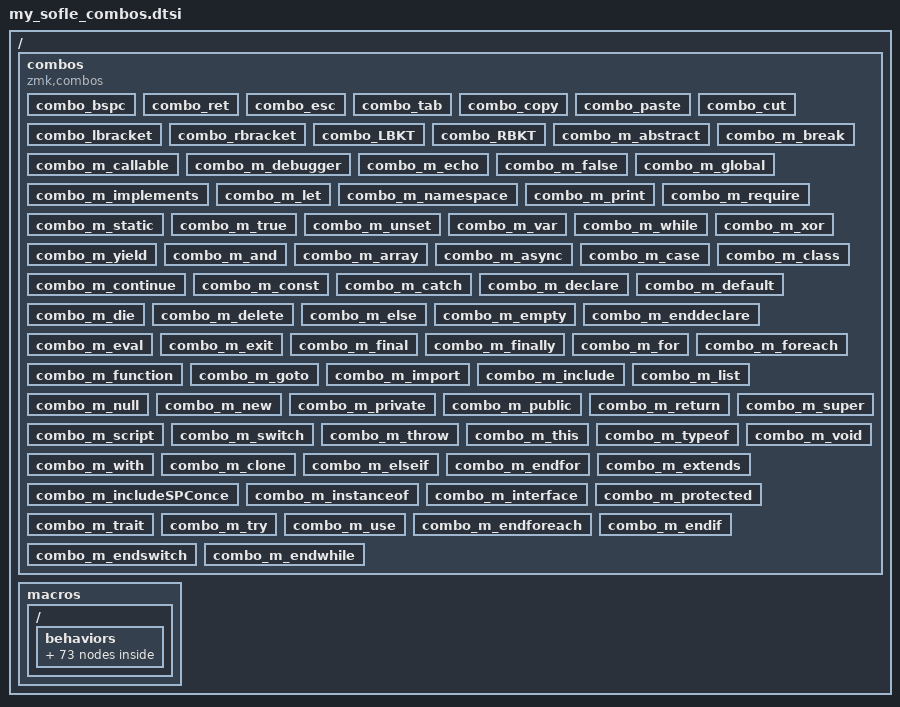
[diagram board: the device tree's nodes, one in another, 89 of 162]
/*                       58 KEY MATRIX 

  ╭────────────────────────────┬────────────────────────────╮
  │  0   1   2   3   4   5     │      6   7   8   9  10  11 │
  │ 12  13  14  15  16  17     │     18  19  20  21  22  23 │
  │ 24  25  26  27  28  29     │     30  31  32  33  34  35 │
  │ 36  37  38  39  40  41  42 │ 43  44  45  46  47  48  49 │
  ╰───────────╮ 50  51  52  53 │ 54  55  56  57 ╭───────────╯
              ╰────────────────┴────────────────╯            */


#define P_Q 13
#define P_W 14
#define P_F 15
#define P_P 16
#define P_B 17
#define P_J 18
#define P_L 19
#define P_U 20
#define P_Y 21
#define P_SEMI 22
#define P_A 25
#define P_R 26
#define P_S 27
#define P_T 28
#define P_G 29
#define P_M 30
#define P_N 31
#define P_E 32
#define P_I 33
#define P_O 34
#define P_Z 37
#define P_X 38
#define P_C 39
#define P_D 40
#define P_V 41
#define P_K 44
#define P_H 45
#define P_COMA 46
#define P_DOT 47
#define P_SQT 48
#define P_COMBO 52 55
#define COMBO_TIMEOUT 200
#define MACRO_TAP 10
#define MACRO_WAIT 0

/ {
    combos {
        compatible = "zmk,combos";
        combo_bspc {
            timeout-ms = <50>;
            key-positions = <19 20>;
            bindings = <&kp BSPC>;
            layers = <0>;
        };
        combo_ret {
            timeout-ms = <50>;
            key-positions = <20 21>;
            bindings = <&kp RET>;
            layers = <0>;
        };
        combo_esc {
            timeout-ms = <50>;
            key-positions = <14 15>;
            bindings = <&kp ESC>;
            layers = <0>;
        };
        combo_tab {
            timeout-ms = <50>;
            key-positions = <15 16>;
            bindings = <&kp TAB>;
            layers = <0>;
        };
        combo_copy {
            timeout-ms = <50>;
            key-positions = <38 39>;
            bindings = <&kp LC(INS)>;
            layers = <4>;
        };
        combo_paste {
            timeout-ms = <50>;
            key-positions = <39 40>;
            bindings = <&kp LS(INS)>;
            layers = <4>;
        };
        combo_cut {
            timeout-ms = <50>;
            key-positions = <37 38>;
            bindings = <&kp LS(DEL)>;
            layers = <4>;
        };
        combo_lbracket {
            timeout-ms = <50>;
            key-positions = <40 41>;
            bindings = <&kp LPAR>;
            layers = <0>;
        };
        combo_rbracket {
            timeout-ms = <50>;
            key-positions = <44 45>;
            bindings = <&kp RPAR>;
            layers = <0>;
        };
        combo_LBKT {
            timeout-ms = <50>;
            key-positions = <16 17>;
            bindings = <&kp LBKT>;
            layers = <0>;
        };
        combo_RBKT {
            timeout-ms = <50>;
            key-positions = <18 19>;
            bindings = <&kp RBKT>;
            layers = <0>;
        };
        // COMBOS START
    combo_m_abstract {
      timeout-ms = <COMBO_TIMEOUT>;
      key-positions = <P_COMBO P_A>;
      bindings = <&m_abstract>;
      layers = <0>;
    };
    combo_m_break {
      timeout-ms = <COMBO_TIMEOUT>;
      key-positions = <P_COMBO P_B>;
      bindings = <&m_break>;
      layers = <0>;
    };
    combo_m_callable {
      timeout-ms = <COMBO_TIMEOUT>;
      key-positions = <P_COMBO P_C>;
      bindings = <&m_callable>;
      layers = <0>;
    };
    combo_m_debugger {
      timeout-ms = <COMBO_TIMEOUT>;
      key-positions = <P_COMBO P_D>;
      bindings = <&m_debugger>;
      layers = <0>;
    };
    combo_m_echo {
      timeout-ms = <COMBO_TIMEOUT>;
      key-positions = <P_COMBO P_E>;
      bindings = <&m_echo>;
      layers = <0>;
    };
    combo_m_false {
      timeout-ms = <COMBO_TIMEOUT>;
      key-positions = <P_COMBO P_F>;
      bindings = <&m_false>;
      layers = <0>;
    };
    combo_m_global {
      timeout-ms = <COMBO_TIMEOUT>;
      key-positions = <P_COMBO P_G>;
      bindings = <&m_global>;
      layers = <0>;
    };
    combo_m_implements {
      timeout-ms = <COMBO_TIMEOUT>;
      key-positions = <P_COMBO P_I>;
      bindings = <&m_implements>;
      layers = <0>;
    };
    combo_m_let {
      timeout-ms = <COMBO_TIMEOUT>;
      key-positions = <P_COMBO P_L>;
      bindings = <&m_let>;
      layers = <0>;
    };
    combo_m_namespace {
      timeout-ms = <COMBO_TIMEOUT>;
      key-positions = <P_COMBO P_N>;
      bindings = <&m_namespace>;
      layers = <0>;
    };
    combo_m_print {
      timeout-ms = <COMBO_TIMEOUT>;
      key-positions = <P_COMBO P_P>;
      bindings = <&m_print>;
      layers = <0>;
    };
    combo_m_require {
      timeout-ms = <COMBO_TIMEOUT>;
      key-positions = <P_COMBO P_R>;
      bindings = <&m_require>;
      layers = <0>;
    };
    combo_m_static {
      timeout-ms = <COMBO_TIMEOUT>;
      key-positions = <P_COMBO P_S>;
      bindings = <&m_static>;
      layers = <0>;
    };
    combo_m_true {
      timeout-ms = <COMBO_TIMEOUT>;
      key-positions = <P_COMBO P_T>;
      bindings = <&m_true>;
      layers = <0>;
    };
    combo_m_unset {
      timeout-ms = <COMBO_TIMEOUT>;
      key-positions = <P_COMBO P_U>;
      bindings = <&m_unset>;
      layers = <0>;
    };
    combo_m_var {
      timeout-ms = <COMBO_TIMEOUT>;
      key-positions = <P_COMBO P_V>;
      bindings = <&m_var>;
      layers = <0>;
    };
    combo_m_while {
      timeout-ms = <COMBO_TIMEOUT>;
      key-positions = <P_COMBO P_W>;
      bindings = <&m_while>;
      layers = <0>;
    };
    combo_m_xor {
      timeout-ms = <COMBO_TIMEOUT>;
      key-positions = <P_COMBO P_X>;
      bindings = <&m_xor>;
      layers = <0>;
    };
    combo_m_yield {
      timeout-ms = <COMBO_TIMEOUT>;
      key-positions = <P_COMBO P_Y>;
      bindings = <&m_yield>;
      layers = <0>;
    };
    combo_m_and {
      timeout-ms = <COMBO_TIMEOUT>;
      key-positions = <P_COMBO P_A P_N>;
      bindings = <&m_and>;
      layers = <0>;
    };
    combo_m_array {
      timeout-ms = <COMBO_TIMEOUT>;
      key-positions = <P_COMBO P_A P_R>;
      bindings = <&m_array>;
      layers = <0>;
    };
    combo_m_async {
      timeout-ms = <COMBO_TIMEOUT>;
      key-positions = <P_COMBO P_A P_Y>;
      bindings = <&m_async>;
      layers = <0>;
    };
    combo_m_case {
      timeout-ms = <COMBO_TIMEOUT>;
      key-positions = <P_COMBO P_C P_A>;
      bindings = <&m_case>;
      layers = <0>;
    };
    combo_m_class {
      timeout-ms = <COMBO_TIMEOUT>;
      key-positions = <P_COMBO P_C P_L>;
      bindings = <&m_class>;
      layers = <0>;
    };
    combo_m_continue {
      timeout-ms = <COMBO_TIMEOUT>;
      key-positions = <P_COMBO P_C P_N>;
      bindings = <&m_continue>;
      layers = <0>;
    };
    combo_m_const {
      timeout-ms = <COMBO_TIMEOUT>;
      key-positions = <P_COMBO P_C P_O>;
      bindings = <&m_const>;
      layers = <0>;
    };
    combo_m_catch {
      timeout-ms = <COMBO_TIMEOUT>;
      key-positions = <P_COMBO P_C P_T>;
      bindings = <&m_catch>;
      layers = <0>;
    };
    combo_m_declare {
      timeout-ms = <COMBO_TIMEOUT>;
      key-positions = <P_COMBO P_D P_E>;
      bindings = <&m_declare>;
      layers = <0>;
    };
    combo_m_default {
      timeout-ms = <COMBO_TIMEOUT>;
      key-positions = <P_COMBO P_D P_F>;
      bindings = <&m_default>;
      layers = <0>;
    };
    combo_m_die {
      timeout-ms = <COMBO_TIMEOUT>;
      key-positions = <P_COMBO P_D P_I>;
      bindings = <&m_die>;
      layers = <0>;
    };
    combo_m_delete {
      timeout-ms = <COMBO_TIMEOUT>;
      key-positions = <P_COMBO P_D P_L>;
      bindings = <&m_delete>;
      layers = <0>;
    };
    combo_m_else {
      timeout-ms = <COMBO_TIMEOUT>;
      key-positions = <P_COMBO P_E P_L>;
      bindings = <&m_else>;
      layers = <0>;
    };
    combo_m_empty {
      timeout-ms = <COMBO_TIMEOUT>;
      key-positions = <P_COMBO P_E P_M>;
      bindings = <&m_empty>;
      layers = <0>;
    };
    combo_m_enddeclare {
      timeout-ms = <COMBO_TIMEOUT>;
      key-positions = <P_COMBO P_E P_N>;
      bindings = <&m_enddeclare>;
      layers = <0>;
    };
    combo_m_eval {
      timeout-ms = <COMBO_TIMEOUT>;
      key-positions = <P_COMBO P_E P_V>;
      bindings = <&m_eval>;
      layers = <0>;
    };
    combo_m_exit {
      timeout-ms = <COMBO_TIMEOUT>;
      key-positions = <P_COMBO P_E P_X>;
      bindings = <&m_exit>;
      layers = <0>;
    };
    combo_m_final {
      timeout-ms = <COMBO_TIMEOUT>;
      key-positions = <P_COMBO P_F P_I>;
      bindings = <&m_final>;
      layers = <0>;
    };
    combo_m_finally {
      timeout-ms = <COMBO_TIMEOUT>;
      key-positions = <P_COMBO P_F P_N>;
      bindings = <&m_finally>;
      layers = <0>;
    };
    combo_m_for {
      timeout-ms = <COMBO_TIMEOUT>;
      key-positions = <P_COMBO P_F P_O>;
      bindings = <&m_for>;
      layers = <0>;
    };
    combo_m_foreach {
      timeout-ms = <COMBO_TIMEOUT>;
      key-positions = <P_COMBO P_F P_R>;
      bindings = <&m_foreach>;
      layers = <0>;
    };
    combo_m_function {
      timeout-ms = <COMBO_TIMEOUT>;
      key-positions = <P_COMBO P_F P_U>;
      bindings = <&m_function>;
      layers = <0>;
    };
    combo_m_goto {
      timeout-ms = <COMBO_TIMEOUT>;
      key-positions = <P_COMBO P_G P_O>;
      bindings = <&m_goto>;
      layers = <0>;
    };
    combo_m_import {
      timeout-ms = <COMBO_TIMEOUT>;
      key-positions = <P_COMBO P_I P_M>;
      bindings = <&m_import>;
      layers = <0>;
    };
    combo_m_include {
      timeout-ms = <COMBO_TIMEOUT>;
      key-positions = <P_COMBO P_I P_N>;
      bindings = <&m_include>;
      layers = <0>;
    };
    combo_m_list {
      timeout-ms = <COMBO_TIMEOUT>;
      key-positions = <P_COMBO P_L P_I>;
      bindings = <&m_list>;
      layers = <0>;
    };
    combo_m_null {
      timeout-ms = <COMBO_TIMEOUT>;
      key-positions = <P_COMBO P_N P_U>;
      bindings = <&m_null>;
      layers = <0>;
    };
    combo_m_new {
      timeout-ms = <COMBO_TIMEOUT>;
      key-positions = <P_COMBO P_N P_W>;
      bindings = <&m_new>;
      layers = <0>;
    };
    combo_m_private {
      timeout-ms = <COMBO_TIMEOUT>;
      key-positions = <P_COMBO P_P P_R>;
      bindings = <&m_private>;
      layers = <0>;
    };
    combo_m_public {
      timeout-ms = <COMBO_TIMEOUT>;
      key-positions = <P_COMBO P_P P_U>;
      bindings = <&m_public>;
      layers = <0>;
    };
    combo_m_return {
      timeout-ms = <COMBO_TIMEOUT>;
      key-positions = <P_COMBO P_R P_T>;
      bindings = <&m_return>;
      layers = <0>;
    };
    combo_m_super {
      timeout-ms = <COMBO_TIMEOUT>;
      key-positions = <P_COMBO P_S P_U>;
      bindings = <&m_super>;
      layers = <0>;
    };
    combo_m_script {
      timeout-ms = <COMBO_TIMEOUT>;
      key-positions = <P_COMBO P_S P_R>;
      bindings = <&m_script>;
      layers = <0>;
    };
    combo_m_switch {
      timeout-ms = <COMBO_TIMEOUT>;
      key-positions = <P_COMBO P_S P_W>;
      bindings = <&m_switch>;
      layers = <0>;
    };
    combo_m_throw {
      timeout-ms = <COMBO_TIMEOUT>;
      key-positions = <P_COMBO P_T P_H>;
      bindings = <&m_throw>;
      layers = <0>;
    };
    combo_m_this {
      timeout-ms = <COMBO_TIMEOUT>;
      key-positions = <P_COMBO P_T P_S>;
      bindings = <&m_this>;
      layers = <0>;
    };
    combo_m_typeof {
      timeout-ms = <COMBO_TIMEOUT>;
      key-positions = <P_COMBO P_T P_Y>;
      bindings = <&m_typeof>;
      layers = <0>;
    };
    combo_m_void {
      timeout-ms = <COMBO_TIMEOUT>;
      key-positions = <P_COMBO P_V P_O>;
      bindings = <&m_void>;
      layers = <0>;
    };
    combo_m_with {
      timeout-ms = <COMBO_TIMEOUT>;
      key-positions = <P_COMBO P_W P_I>;
      bindings = <&m_with>;
      layers = <0>;
    };
    combo_m_clone {
      timeout-ms = <COMBO_TIMEOUT>;
      key-positions = <P_COMBO P_C P_L P_O>;
      bindings = <&m_clone>;
      layers = <0>;
    };
    combo_m_elseif {
      timeout-ms = <COMBO_TIMEOUT>;
      key-positions = <P_COMBO P_E P_L P_S>;
      bindings = <&m_elseif>;
      layers = <0>;
    };
    combo_m_endfor {
      timeout-ms = <COMBO_TIMEOUT>;
      key-positions = <P_COMBO P_E P_N P_D>;
      bindings = <&m_endfor>;
      layers = <0>;
    };
    combo_m_extends {
      timeout-ms = <COMBO_TIMEOUT>;
      key-positions = <P_COMBO P_E P_X P_T>;
      bindings = <&m_extends>;
      layers = <0>;
    };
    combo_m_includeSPConce {
      timeout-ms = <COMBO_TIMEOUT>;
      key-positions = <P_COMBO P_I P_N P_C>;
      bindings = <&m_includeSPConce>;
      layers = <0>;
    };
    combo_m_instanceof {
      timeout-ms = <COMBO_TIMEOUT>;
      key-positions = <P_COMBO P_I P_N P_S>;
      bindings = <&m_instanceof>;
      layers = <0>;
    };
    combo_m_interface {
      timeout-ms = <COMBO_TIMEOUT>;
      key-positions = <P_COMBO P_I P_N P_T>;
      bindings = <&m_interface>;
      layers = <0>;
    };
    combo_m_protected {
      timeout-ms = <COMBO_TIMEOUT>;
      key-positions = <P_COMBO P_P P_R P_O>;
      bindings = <&m_protected>;
      layers = <0>;
    };
    combo_m_trait {
      timeout-ms = <COMBO_TIMEOUT>;
      key-positions = <P_COMBO P_T P_R P_A>;
      bindings = <&m_trait>;
      layers = <0>;
    };
    combo_m_try {
      timeout-ms = <COMBO_TIMEOUT>;
      key-positions = <P_COMBO P_T P_R P_Y>;
      bindings = <&m_try>;
      layers = <0>;
    };
    combo_m_use {
      timeout-ms = <COMBO_TIMEOUT>;
      key-positions = <P_COMBO P_U P_S P_E>;
      bindings = <&m_use>;
      layers = <0>;
    };
    combo_m_endforeach {
      timeout-ms = <COMBO_TIMEOUT>;
      key-positions = <P_COMBO P_E P_N P_D P_F>;
      bindings = <&m_endforeach>;
      layers = <0>;
    };
    combo_m_endif {
      timeout-ms = <COMBO_TIMEOUT>;
      key-positions = <P_COMBO P_E P_N P_D P_I>;
      bindings = <&m_endif>;
      layers = <0>;
    };
    combo_m_endswitch {
      timeout-ms = <COMBO_TIMEOUT>;
      key-positions = <P_COMBO P_E P_N P_D P_S>;
      bindings = <&m_endswitch>;
      layers = <0>;
    };
    combo_m_endwhile {
      timeout-ms = <COMBO_TIMEOUT>;
      key-positions = <P_COMBO P_E P_N P_D P_W>;
      bindings = <&m_endwhile>;
      layers = <0>;
    };

        // COMBOS END
    };
    macros {
          // MACROS START
    ZMK_MACRO(m_abstract,
        wait-ms = <MACRO_WAIT>;
        tap-ms = <MACRO_TAP>;
        bindings = <&kp A &kp B &kp S &kp T &kp R &kp A &kp C &kp T &kp SPACE>;
    )
    ZMK_MACRO(m_break,
        wait-ms = <MACRO_WAIT>;
        tap-ms = <MACRO_TAP>;
        bindings = <&kp B &kp R &kp E &kp A &kp K &kp SPACE>;
    )
    ZMK_MACRO(m_callable,
        wait-ms = <MACRO_WAIT>;
        tap-ms = <MACRO_TAP>;
        bindings = <&kp C &kp A &kp L &kp L &kp A &kp B &kp L &kp E &kp SPACE>;
    )
    ZMK_MACRO(m_debugger,
        wait-ms = <MACRO_WAIT>;
        tap-ms = <MACRO_TAP>;
        bindings = <&kp D &kp E &kp B &kp U &kp G &kp G &kp E &kp R &kp SPACE>;
    )
    ZMK_MACRO(m_echo,
        wait-ms = <MACRO_WAIT>;
        tap-ms = <MACRO_TAP>;
        bindings = <&kp E &kp C &kp H &kp O &kp SPACE>;
    )
    ZMK_MACRO(m_false,
        wait-ms = <MACRO_WAIT>;
        tap-ms = <MACRO_TAP>;
        bindings = <&kp F &kp A &kp L &kp S &kp E &kp SPACE>;
    )
    ZMK_MACRO(m_global,
        wait-ms = <MACRO_WAIT>;
        tap-ms = <MACRO_TAP>;
        bindings = <&kp G &kp L &kp O &kp B &kp A &kp L &kp SPACE>;
    )
    ZMK_MACRO(m_implements,
        wait-ms = <MACRO_WAIT>;
        tap-ms = <MACRO_TAP>;
        bindings = <&kp I &kp M &kp P &kp L &kp E &kp M &kp E &kp N &kp T &kp S &kp SPACE>;
    )
    ZMK_MACRO(m_let,
        wait-ms = <MACRO_WAIT>;
        tap-ms = <MACRO_TAP>;
        bindings = <&kp L &kp E &kp T &kp SPACE>;
    )
    ZMK_MACRO(m_namespace,
        wait-ms = <MACRO_WAIT>;
        tap-ms = <MACRO_TAP>;
        bindings = <&kp N &kp A &kp M &kp E &kp S &kp P &kp A &kp C &kp E &kp SPACE>;
    )
    ZMK_MACRO(m_print,
        wait-ms = <MACRO_WAIT>;
        tap-ms = <MACRO_TAP>;
        bindings = <&kp P &kp R &kp I &kp N &kp T &kp SPACE>;
    )
    ZMK_MACRO(m_require,
        wait-ms = <MACRO_WAIT>;
        tap-ms = <MACRO_TAP>;
        bindings = <&kp R &kp E &kp Q &kp U &kp I &kp R &kp E &kp SPACE>;
    )
    ZMK_MACRO(m_static,
        wait-ms = <MACRO_WAIT>;
        tap-ms = <MACRO_TAP>;
        bindings = <&kp S &kp T &kp A &kp T &kp I &kp C &kp SPACE>;
    )
    ZMK_MACRO(m_true,
        wait-ms = <MACRO_WAIT>;
        tap-ms = <MACRO_TAP>;
        bindings = <&kp T &kp R &kp U &kp E &kp SPACE>;
    )
    ZMK_MACRO(m_unset,
        wait-ms = <MACRO_WAIT>;
        tap-ms = <MACRO_TAP>;
        bindings = <&kp U &kp N &kp S &kp E &kp T &kp SPACE>;
    )
    ZMK_MACRO(m_var,
        wait-ms = <MACRO_WAIT>;
        tap-ms = <MACRO_TAP>;
        bindings = <&kp V &kp A &kp R &kp SPACE>;
    )
    ZMK_MACRO(m_while,
        wait-ms = <MACRO_WAIT>;
        tap-ms = <MACRO_TAP>;
        bindings = <&kp W &kp H &kp I &kp L &kp E &kp SPACE>;
    )
    ZMK_MACRO(m_xor,
        wait-ms = <MACRO_WAIT>;
        tap-ms = <MACRO_TAP>;
        bindings = <&kp X &kp O &kp R &kp SPACE>;
    )
    ZMK_MACRO(m_yield,
        wait-ms = <MACRO_WAIT>;
        tap-ms = <MACRO_TAP>;
        bindings = <&kp Y &kp I &kp E &kp L &kp D &kp SPACE>;
    )
    ZMK_MACRO(m_and,
        wait-ms = <MACRO_WAIT>;
        tap-ms = <MACRO_TAP>;
        bindings = <&kp A &kp N &kp D &kp SPACE>;
    )
    ZMK_MACRO(m_array,
        wait-ms = <MACRO_WAIT>;
        tap-ms = <MACRO_TAP>;
        bindings = <&kp A &kp R &kp R &kp A &kp Y &kp SPACE>;
    )
    ZMK_MACRO(m_async,
        wait-ms = <MACRO_WAIT>;
        tap-ms = <MACRO_TAP>;
        bindings = <&kp A &kp S &kp Y &kp N &kp C &kp SPACE>;
    )
    ZMK_MACRO(m_case,
        wait-ms = <MACRO_WAIT>;
        tap-ms = <MACRO_TAP>;
        bindings = <&kp C &kp A &kp S &kp E &kp SPACE>;
    )
    ZMK_MACRO(m_class,
        wait-ms = <MACRO_WAIT>;
        tap-ms = <MACRO_TAP>;
        bindings = <&kp C &kp L &kp A &kp S &kp S &kp SPACE>;
    )
    ZMK_MACRO(m_continue,
        wait-ms = <MACRO_WAIT>;
        tap-ms = <MACRO_TAP>;
        bindings = <&kp C &kp O &kp N &kp T &kp I &kp N &kp U &kp E &kp SPACE>;
    )
    ZMK_MACRO(m_const,
        wait-ms = <MACRO_WAIT>;
        tap-ms = <MACRO_TAP>;
        bindings = <&kp C &kp O &kp N &kp S &kp T &kp SPACE>;
    )
    ZMK_MACRO(m_catch,
        wait-ms = <MACRO_WAIT>;
        tap-ms = <MACRO_TAP>;
        bindings = <&kp C &kp A &kp T &kp C &kp H &kp SPACE>;
    )
    ZMK_MACRO(m_declare,
        wait-ms = <MACRO_WAIT>;
        tap-ms = <MACRO_TAP>;
        bindings = <&kp D &kp E &kp C &kp L &kp A &kp R &kp E &kp SPACE>;
    )
    ZMK_MACRO(m_default,
        wait-ms = <MACRO_WAIT>;
        tap-ms = <MACRO_TAP>;
        bindings = <&kp D &kp E &kp F &kp A &kp U &kp L &kp T &kp SPACE>;
    )
    ZMK_MACRO(m_die,
        wait-ms = <MACRO_WAIT>;
        tap-ms = <MACRO_TAP>;
        bindings = <&kp D &kp I &kp E &kp SPACE>;
    )
    ZMK_MACRO(m_delete,
        wait-ms = <MACRO_WAIT>;
        tap-ms = <MACRO_TAP>;
        bindings = <&kp D &kp E &kp L &kp E &kp T &kp E &kp SPACE>;
    )
    ZMK_MACRO(m_else,
        wait-ms = <MACRO_WAIT>;
        tap-ms = <MACRO_TAP>;
        bindings = <&kp E &kp L &kp S &kp E &kp SPACE>;
    )
    ZMK_MACRO(m_empty,
        wait-ms = <MACRO_WAIT>;
        tap-ms = <MACRO_TAP>;
        bindings = <&kp E &kp M &kp P &kp T &kp Y &kp SPACE>;
    )
    ZMK_MACRO(m_enddeclare,
        wait-ms = <MACRO_WAIT>;
        tap-ms = <MACRO_TAP>;
        bindings = <&kp E &kp N &kp D &kp D &kp E &kp C &kp L &kp A &kp R &kp E &kp SPACE>;
    )
    ZMK_MACRO(m_eval,
        wait-ms = <MACRO_WAIT>;
        tap-ms = <MACRO_TAP>;
        bindings = <&kp E &kp V &kp A &kp L &kp SPACE>;
    )
    ZMK_MACRO(m_exit,
        wait-ms = <MACRO_WAIT>;
        tap-ms = <MACRO_TAP>;
        bindings = <&kp E &kp X &kp I &kp T &kp SPACE>;
    )
    ZMK_MACRO(m_final,
        wait-ms = <MACRO_WAIT>;
        tap-ms = <MACRO_TAP>;
        bindings = <&kp F &kp I &kp N &kp A &kp L &kp SPACE>;
    )
    ZMK_MACRO(m_finally,
        wait-ms = <MACRO_WAIT>;
        tap-ms = <MACRO_TAP>;
        bindings = <&kp F &kp I &kp N &kp A &kp L &kp L &kp Y &kp SPACE>;
    )
    ZMK_MACRO(m_for,
        wait-ms = <MACRO_WAIT>;
        tap-ms = <MACRO_TAP>;
        bindings = <&kp F &kp O &kp R &kp SPACE>;
    )
    ZMK_MACRO(m_foreach,
        wait-ms = <MACRO_WAIT>;
        tap-ms = <MACRO_TAP>;
        bindings = <&kp F &kp O &kp R &kp E &kp A &kp C &kp H &kp SPACE>;
    )
    ZMK_MACRO(m_function,
        wait-ms = <MACRO_WAIT>;
        tap-ms = <MACRO_TAP>;
        bindings = <&kp F &kp U &kp N &kp C &kp T &kp I &kp O &kp N &kp SPACE>;
    )
    ZMK_MACRO(m_goto,
        wait-ms = <MACRO_WAIT>;
        tap-ms = <MACRO_TAP>;
        bindings = <&kp G &kp O &kp T &kp O &kp SPACE>;
    )
    ZMK_MACRO(m_import,
        wait-ms = <MACRO_WAIT>;
        tap-ms = <MACRO_TAP>;
        bindings = <&kp I &kp M &kp P &kp O &kp R &kp T &kp SPACE>;
    )
    ZMK_MACRO(m_include,
        wait-ms = <MACRO_WAIT>;
        tap-ms = <MACRO_TAP>;
        bindings = <&kp I &kp N &kp C &kp L &kp U &kp D &kp E &kp SPACE>;
    )
    ZMK_MACRO(m_list,
        wait-ms = <MACRO_WAIT>;
        tap-ms = <MACRO_TAP>;
        bindings = <&kp L &kp I &kp S &kp T &kp SPACE>;
    )
    ZMK_MACRO(m_null,
        wait-ms = <MACRO_WAIT>;
        tap-ms = <MACRO_TAP>;
        bindings = <&kp N &kp U &kp L &kp L &kp SPACE>;
    )
    ZMK_MACRO(m_new,
        wait-ms = <MACRO_WAIT>;
        tap-ms = <MACRO_TAP>;
        bindings = <&kp N &kp E &kp W &kp SPACE>;
    )
    ZMK_MACRO(m_private,
        wait-ms = <MACRO_WAIT>;
        tap-ms = <MACRO_TAP>;
        bindings = <&kp P &kp R &kp I &kp V &kp A &kp T &kp E &kp SPACE>;
    )
    ZMK_MACRO(m_public,
        wait-ms = <MACRO_WAIT>;
        tap-ms = <MACRO_TAP>;
        bindings = <&kp P &kp U &kp B &kp L &kp I &kp C &kp SPACE>;
    )
    ZMK_MACRO(m_return,
        wait-ms = <MACRO_WAIT>;
        tap-ms = <MACRO_TAP>;
        bindings = <&kp R &kp E &kp T &kp U &kp R &kp N &kp SPACE>;
    )
    ZMK_MACRO(m_super,
        wait-ms = <MACRO_WAIT>;
        tap-ms = <MACRO_TAP>;
        bindings = <&kp S &kp U &kp P &kp E &kp R &kp SPACE>;
    )
    ZMK_MACRO(m_script,
        wait-ms = <MACRO_WAIT>;
        tap-ms = <MACRO_TAP>;
        bindings = <&kp S &kp C &kp R &kp I &kp P &kp T &kp SPACE>;
    )
    ZMK_MACRO(m_switch,
        wait-ms = <MACRO_WAIT>;
        tap-ms = <MACRO_TAP>;
        bindings = <&kp S &kp W &kp I &kp T &kp C &kp H &kp SPACE>;
    )
    ZMK_MACRO(m_throw,
        wait-ms = <MACRO_WAIT>;
        tap-ms = <MACRO_TAP>;
        bindings = <&kp T &kp H &kp R &kp O &kp W &kp SPACE>;
    )
    ZMK_MACRO(m_this,
        wait-ms = <MACRO_WAIT>;
        tap-ms = <MACRO_TAP>;
        bindings = <&kp T &kp H &kp I &kp S &kp SPACE>;
    )
    ZMK_MACRO(m_typeof,
        wait-ms = <MACRO_WAIT>;
        tap-ms = <MACRO_TAP>;
        bindings = <&kp T &kp Y &kp P &kp E &kp O &kp F &kp SPACE>;
    )
    ZMK_MACRO(m_void,
        wait-ms = <MACRO_WAIT>;
        tap-ms = <MACRO_TAP>;
        bindings = <&kp V &kp O &kp I &kp D &kp SPACE>;
    )
    ZMK_MACRO(m_with,
        wait-ms = <MACRO_WAIT>;
        tap-ms = <MACRO_TAP>;
        bindings = <&kp W &kp I &kp T &kp H &kp SPACE>;
    )
    ZMK_MACRO(m_clone,
        wait-ms = <MACRO_WAIT>;
        tap-ms = <MACRO_TAP>;
        bindings = <&kp C &kp L &kp O &kp N &kp E &kp SPACE>;
    )
    ZMK_MACRO(m_elseif,
        wait-ms = <MACRO_WAIT>;
        tap-ms = <MACRO_TAP>;
        bindings = <&kp E &kp L &kp S &kp E &kp I &kp F &kp SPACE>;
    )
    ZMK_MACRO(m_endfor,
        wait-ms = <MACRO_WAIT>;
        tap-ms = <MACRO_TAP>;
        bindings = <&kp E &kp N &kp D &kp F &kp O &kp R &kp SPACE>;
    )
    ZMK_MACRO(m_extends,
        wait-ms = <MACRO_WAIT>;
        tap-ms = <MACRO_TAP>;
        bindings = <&kp E &kp X &kp T &kp E &kp N &kp D &kp S &kp SPACE>;
    )
    ZMK_MACRO(m_includeSPConce,
        wait-ms = <MACRO_WAIT>;
        tap-ms = <MACRO_TAP>;
        bindings = <&kp I &kp N &kp C &kp L &kp U &kp D &kp E &kp SPC &kp O &kp N &kp C &kp E &kp SPACE>;
    )
    ZMK_MACRO(m_instanceof,
        wait-ms = <MACRO_WAIT>;
        tap-ms = <MACRO_TAP>;
        bindings = <&kp I &kp N &kp S &kp T &kp A &kp N &kp C &kp E &kp O &kp F &kp SPACE>;
    )
    ZMK_MACRO(m_interface,
        wait-ms = <MACRO_WAIT>;
        tap-ms = <MACRO_TAP>;
        bindings = <&kp I &kp N &kp T &kp E &kp R &kp F &kp A &kp C &kp E &kp SPACE>;
    )
    ZMK_MACRO(m_protected,
        wait-ms = <MACRO_WAIT>;
        tap-ms = <MACRO_TAP>;
        bindings = <&kp P &kp R &kp O &kp T &kp E &kp C &kp T &kp E &kp D &kp SPACE>;
    )
    ZMK_MACRO(m_trait,
        wait-ms = <MACRO_WAIT>;
        tap-ms = <MACRO_TAP>;
        bindings = <&kp T &kp R &kp A &kp I &kp T &kp SPACE>;
    )
    ZMK_MACRO(m_try,
        wait-ms = <MACRO_WAIT>;
        tap-ms = <MACRO_TAP>;
        bindings = <&kp T &kp R &kp Y &kp SPACE>;
    )
    ZMK_MACRO(m_use,
        wait-ms = <MACRO_WAIT>;
        tap-ms = <MACRO_TAP>;
        bindings = <&kp U &kp S &kp E &kp SPACE>;
    )
    ZMK_MACRO(m_endforeach,
        wait-ms = <MACRO_WAIT>;
        tap-ms = <MACRO_TAP>;
        bindings = <&kp E &kp N &kp D &kp F &kp O &kp R &kp E &kp A &kp C &kp H &kp SPACE>;
    )
    ZMK_MACRO(m_endif,
        wait-ms = <MACRO_WAIT>;
        tap-ms = <MACRO_TAP>;
        bindings = <&kp E &kp N &kp D &kp I &kp F &kp SPACE>;
    )
    ZMK_MACRO(m_endswitch,
        wait-ms = <MACRO_WAIT>;
        tap-ms = <MACRO_TAP>;
        bindings = <&kp E &kp N &kp D &kp S &kp W &kp I &kp T &kp C &kp H &kp SPACE>;
    )
    ZMK_MACRO(m_endwhile,
        wait-ms = <MACRO_WAIT>;
        tap-ms = <MACRO_TAP>;
        bindings = <&kp E &kp N &kp D &kp W &kp H &kp I &kp L &kp E &kp SPACE>;
    )

          // MACROS END
    };
};
